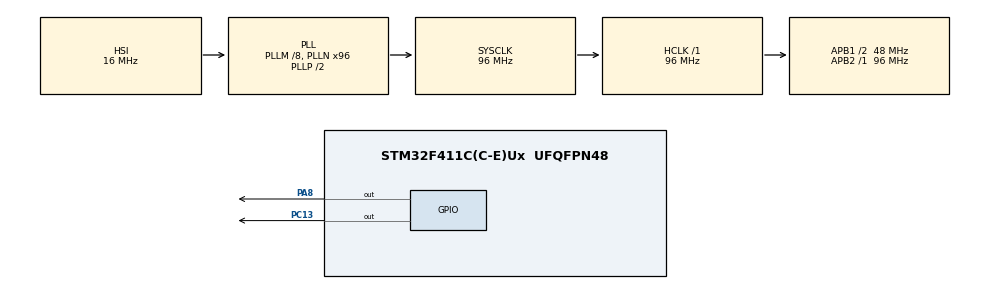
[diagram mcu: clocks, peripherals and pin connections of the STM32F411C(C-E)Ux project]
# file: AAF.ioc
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Mcu.Family=STM32F4
Mcu.Name=STM32F411C(C-E)Ux
Mcu.Package=UFQFPN48
NVIC.PriorityGroup=NVIC_PRIORITYGROUP_4
PA13.Mode=Serial_Wire
PA13.Signal=SYS_JTMS-SWDIO
PA14.Mode=Serial_Wire
PA14.Signal=SYS_JTCK-SWCLK
PA8.Signal=GPIO_Output
PC13-ANTI_TAMP.Signal=GPIO_Output
PH0\ -\ OSC_IN.Mode=HSE-External-Oscillator
PH0\ -\ OSC_IN.Signal=RCC_OSC_IN
PH1\ -\ OSC_OUT.Mode=HSE-External-Oscillator
PH1\ -\ OSC_OUT.Signal=RCC_OSC_OUT
ProjectManager.HeapSize=0x200
ProjectManager.StackSize=0x400
ProjectManager.TargetToolchain=STM32CubeIDE
RCC.48MHZClocksFreq_Value=48000000
RCC.AHBFreq_Value=96000000
RCC.APB1CLKDivider=RCC_HCLK_DIV2
RCC.APB1Freq_Value=48000000
RCC.APB1TimFreq_Value=96000000
RCC.APB2Freq_Value=96000000
RCC.APB2TimFreq_Value=96000000
RCC.CortexFreq_Value=96000000
RCC.HCLKFreq_Value=96000000
RCC.HSE_VALUE=25000000
RCC.HSI_VALUE=16000000
RCC.LSE_VALUE=32768
RCC.PLLM=8
RCC.PLLN=96
RCC.SYSCLKFreq_VALUE=96000000
RCC.SYSCLKSource=RCC_SYSCLKSOURCE_PLLCLK
RCC.VCOOutputFreq_Value=192000000
TIM1.AutoReloadPreload=TIM_AUTORELOAD_PRELOAD_DISABLE
TIM1.Prescaler=95
VP_TIM1_VS_ClockSourceINT.Mode=Internal
board=custom

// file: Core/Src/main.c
/* USER CODE BEGIN Header */
/**
 ******************************************************************************
 * @file           : main.c
 * @brief          : Main program body
 ******************************************************************************
 * @attention
 *
 * Copyright (c) 2024 STMicroelectronics.
 * All rights reserved.
 *
 * This software is licensed under terms that can be found in the LICENSE file
 * in the root directory of this software component.
 * If no LICENSE file comes with this software, it is provided AS-IS.
 *
 ******************************************************************************
 */
/* USER CODE END Header */
#include "main.h"

/* USER CODE BEGIN Includes */
#include "AAF.h"

/* USER CODE END Includes */

TIM_HandleTypeDef htim1;

void SystemClock_Config(void);
static void MX_GPIO_Init(void);
static void MX_TIM1_Init(void);

int main(void)
{

  /* MCU Configuration--------------------------------------------------------*/

  /* Reset of all peripherals, Initializes the Flash interface and the Systick. */
  HAL_Init();

  /* Configure the system clock */
  SystemClock_Config();

  /* Initialize all configured peripherals */
  MX_GPIO_Init();
  MX_TIM1_Init();
  /* USER CODE BEGIN 2 */
	HAL_TIM_Base_Start(&htim1);
  /* USER CODE END 2 */

  /* Infinite loop */
	while (1) {

    /* USER CODE BEGIN 3 */
		HAL_GPIO_TogglePin(GPIOC, GPIO_PIN_13);
		delayMicroseconds(50000);
	}
  /* USER CODE END 3 */
}

void SystemClock_Config(void)
{
  RCC_OscInitTypeDef RCC_OscInitStruct = {0};
  RCC_ClkInitTypeDef RCC_ClkInitStruct = {0};

  /** Configure the main internal regulator output voltage
  */
  __HAL_RCC_PWR_CLK_ENABLE();
  __HAL_PWR_VOLTAGESCALING_CONFIG(PWR_REGULATOR_VOLTAGE_SCALE1);

  /** Initializes the RCC Oscillators according to the specified parameters
  * in the RCC_OscInitTypeDef structure.
  */
  RCC_OscInitStruct.OscillatorType = RCC_OSCILLATORTYPE_HSI;
  RCC_OscInitStruct.HSIState = RCC_HSI_ON;
  RCC_OscInitStruct.HSICalibrationValue = RCC_HSICALIBRATION_DEFAULT;
  RCC_OscInitStruct.PLL.PLLState = RCC_PLL_ON;
  RCC_OscInitStruct.PLL.PLLSource = RCC_PLLSOURCE_HSI;
  RCC_OscInitStruct.PLL.PLLM = 8;
  RCC_OscInitStruct.PLL.PLLN = 96;
  RCC_OscInitStruct.PLL.PLLP = RCC_PLLP_DIV2;
  RCC_OscInitStruct.PLL.PLLQ = 4;
  if (HAL_RCC_OscConfig(&RCC_OscInitStruct) != HAL_OK)
  {
    Error_Handler();
  }

  /** Initializes the CPU, AHB and APB buses clocks
  */
  RCC_ClkInitStruct.ClockType = RCC_CLOCKTYPE_HCLK|RCC_CLOCKTYPE_SYSCLK
                              |RCC_CLOCKTYPE_PCLK1|RCC_CLOCKTYPE_PCLK2;
  RCC_ClkInitStruct.SYSCLKSource = RCC_SYSCLKSOURCE_PLLCLK;
  RCC_ClkInitStruct.AHBCLKDivider = RCC_SYSCLK_DIV1;
  RCC_ClkInitStruct.APB1CLKDivider = RCC_HCLK_DIV2;
  RCC_ClkInitStruct.APB2CLKDivider = RCC_HCLK_DIV1;

  if (HAL_RCC_ClockConfig(&RCC_ClkInitStruct, FLASH_LATENCY_3) != HAL_OK)
  {
    Error_Handler();
  }
}

static void MX_TIM1_Init(void)
{

  TIM_ClockConfigTypeDef sClockSourceConfig = {0};
  TIM_MasterConfigTypeDef sMasterConfig = {0};

  htim1.Instance = TIM1;
  htim1.Init.Prescaler = 95;
  htim1.Init.CounterMode = TIM_COUNTERMODE_UP;
  htim1.Init.Period = 65535;
  htim1.Init.ClockDivision = TIM_CLOCKDIVISION_DIV1;
  htim1.Init.RepetitionCounter = 0;
  htim1.Init.AutoReloadPreload = TIM_AUTORELOAD_PRELOAD_DISABLE;
  if (HAL_TIM_Base_Init(&htim1) != HAL_OK)
  {
    Error_Handler();
  }
  sClockSourceConfig.ClockSource = TIM_CLOCKSOURCE_INTERNAL;
  if (HAL_TIM_ConfigClockSource(&htim1, &sClockSourceConfig) != HAL_OK)
  {
    Error_Handler();
  }
  sMasterConfig.MasterOutputTrigger = TIM_TRGO_RESET;
  sMasterConfig.MasterSlaveMode = TIM_MASTERSLAVEMODE_DISABLE;
  if (HAL_TIMEx_MasterConfigSynchronization(&htim1, &sMasterConfig) != HAL_OK)
  {
    Error_Handler();
  }

}

static void MX_GPIO_Init(void)
{
  GPIO_InitTypeDef GPIO_InitStruct = {0};

  /* GPIO Ports Clock Enable */
  __HAL_RCC_GPIOC_CLK_ENABLE();
  __HAL_RCC_GPIOH_CLK_ENABLE();
  __HAL_RCC_GPIOA_CLK_ENABLE();

  /*Configure GPIO pin Output Level */
  HAL_GPIO_WritePin(GPIOC, GPIO_PIN_13, GPIO_PIN_RESET);

  /*Configure GPIO pin Output Level */
  HAL_GPIO_WritePin(GPIOA, GPIO_PIN_8, GPIO_PIN_RESET);

  /*Configure GPIO pin : PC13 */
  GPIO_InitStruct.Pin = GPIO_PIN_13;
  GPIO_InitStruct.Mode = GPIO_MODE_OUTPUT_PP;
  GPIO_InitStruct.Pull = GPIO_NOPULL;
  GPIO_InitStruct.Speed = GPIO_SPEED_FREQ_LOW;
  HAL_GPIO_Init(GPIOC, &GPIO_InitStruct);

  /*Configure GPIO pin : PA8 */
  GPIO_InitStruct.Pin = GPIO_PIN_8;
  GPIO_InitStruct.Mode = GPIO_MODE_OUTPUT_PP;
  GPIO_InitStruct.Pull = GPIO_NOPULL;
  GPIO_InitStruct.Speed = GPIO_SPEED_FREQ_LOW;
  HAL_GPIO_Init(GPIOA, &GPIO_InitStruct);

}

void Error_Handler(void)
{
	__disable_irq();
	while (1) {
	}
}
